BO_ 80 MSG_04: 8 XXX
 SG_ SIGNAL : 24|1@0+ (1,0) [0|1] "" XXX
 SG_ NEW_SIGNAL_1 : 25|1@0+ (1,0) [0|1] "" XXX

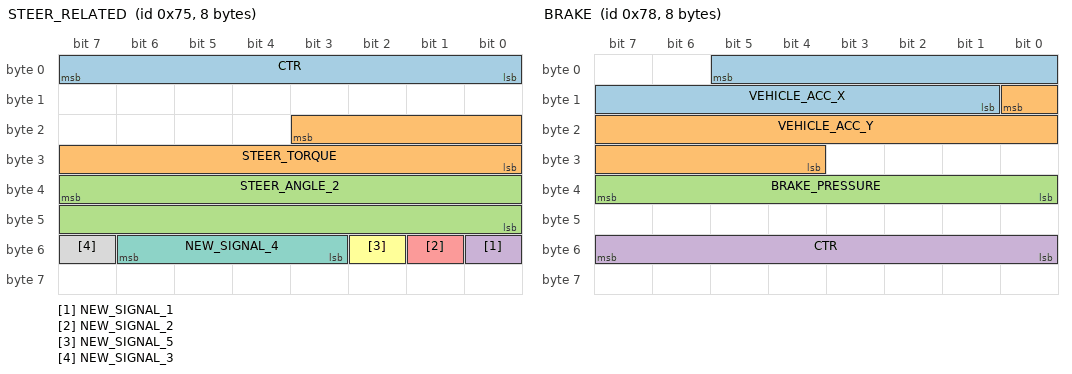
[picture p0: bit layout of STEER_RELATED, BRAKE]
BO_ 117 STEER_RELATED: 8 XXX
 SG_ CTR : 7|8@0+ (1,0) [0|255] "" XXX
 SG_ STEER_TORQUE : 19|12@0+ (1,-2000) [0|255] "" XXX
 SG_ STEER_ANGLE_2 : 39|16@0+ (0.1,-1800) [0|131071] "" XXX
 SG_ NEW_SIGNAL_1 : 48|1@0+ (1,0) [0|1] "" XXX
 SG_ NEW_SIGNAL_2 : 49|1@0+ (1,0) [0|1] "" XXX
 SG_ NEW_SIGNAL_5 : 50|1@0+ (1,0) [0|1] "" XXX
 SG_ NEW_SIGNAL_4 : 54|4@0+ (1,0) [0|31] "" XXX
 SG_ NEW_SIGNAL_3 : 55|1@0+ (1,0) [0|63] "" XXX

BO_ 118 RPM_RELATED: 8 XXX
 SG_ CTR : 7|8@0+ (1,0) [0|127] "" XXX
 SG_ NEW_SIGNAL_2 : 19|12@0+ (1,0) [0|4095] "" XXX

BO_ 120 BRAKE: 8 XXX
 SG_ VEHICLE_ACC_X : 5|13@0+ (0.01,-40) [-40|40] "m/s^2" XXX
 SG_ VEHICLE_ACC_Y : 8|13@0+ (0.001,-4.096) [-4.096|4.096] "m/s^2" XXX
 SG_ BRAKE_PRESSURE : 39|8@0+ (1,0) [0|255] "" XXX
 SG_ CTR : 55|8@0+ (1,0) [0|255] "" XXX

BO_ 121 Lateral_Acceleration: 2 XXX
 SG_ LateralAcceleration : 5|13@0+ (1,0) [0|8191] "" XXX
 SG_ LateralAcceleration_Qf : 6|2@1+ (1,0) [0|3] "" XXX

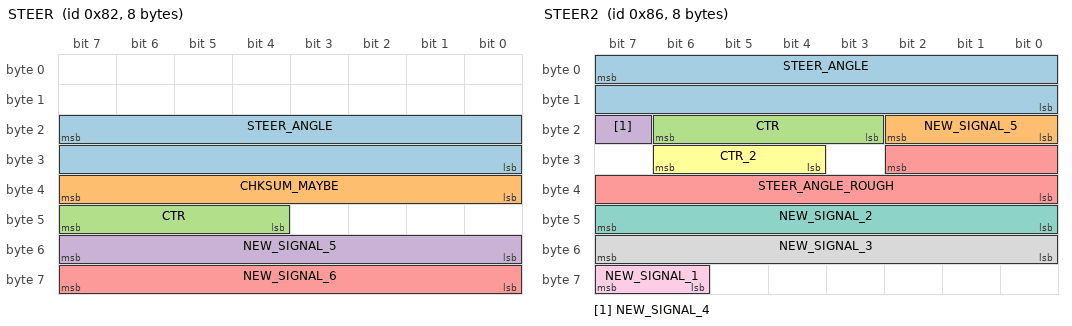
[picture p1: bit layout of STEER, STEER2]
BO_ 130 STEER: 8 XXX
 SG_ STEER_ANGLE : 23|16@0+ (0.05,-1600) [500|-500] "deg" XXX
 SG_ CHKSUM_MAYBE : 39|8@0+ (1,0) [0|255] "" XXX
 SG_ CTR : 47|4@0+ (1,0) [0|255] "" XXX
 SG_ NEW_SIGNAL_5 : 55|8@0+ (1,0) [0|255] "" XXX
 SG_ NEW_SIGNAL_6 : 63|8@0+ (1,0) [0|255] "" XXX

BO_ 134 STEER2: 8 XXX
 SG_ STEER_ANGLE : 7|16@0+ (0.1,-1600) [-500|500] "deg" XXX
 SG_ NEW_SIGNAL_5 : 18|3@0+ (1,0) [0|1] "" XXX
 SG_ CTR : 22|4@0+ (1,0) [0|7] "" XXX
 SG_ NEW_SIGNAL_4 : 23|1@0+ (1,0) [0|1] "" XXX
 SG_ STEER_ANGLE_ROUGH : 26|11@0+ (1,-1000) [0|15] "" XXX
 SG_ CTR_2 : 28|3@1+ (1,0) [0|7] "" XXX
 SG_ NEW_SIGNAL_2 : 47|8@0+ (1,0) [0|7] "" XXX
 SG_ NEW_SIGNAL_3 : 55|8@0+ (1,0) [0|255] "" XXX
 SG_ NEW_SIGNAL_1 : 63|2@0+ (1,0) [0|3] "" XXX

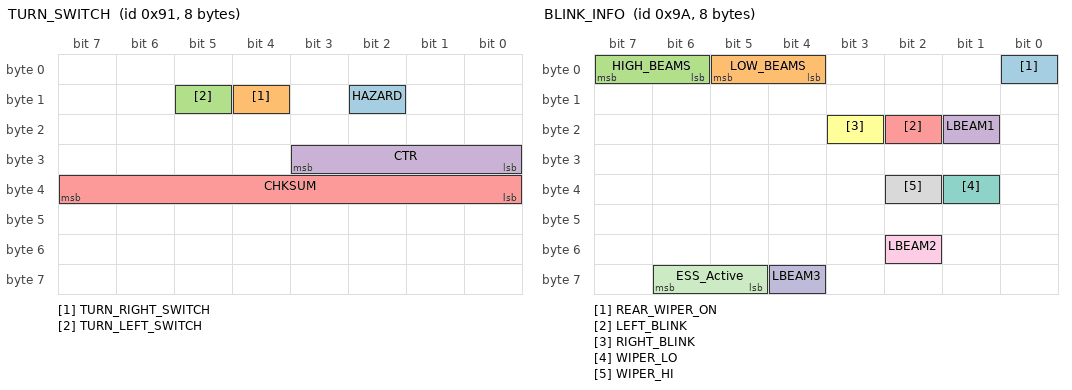
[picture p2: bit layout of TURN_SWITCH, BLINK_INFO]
BO_ 145 TURN_SWITCH: 8 XXX
 SG_ HAZARD : 10|1@0+ (1,0) [0|1] "" XXX
 SG_ TURN_RIGHT_SWITCH : 12|1@0+ (1,0) [0|3] "" XXX
 SG_ TURN_LEFT_SWITCH : 13|1@0+ (1,0) [0|255] "" XXX
 SG_ CTR : 27|4@0+ (1,0) [0|255] "" XXX
 SG_ CHKSUM : 39|8@0+ (1,0) [0|15] "" XXX

BO_ 154 BLINK_INFO: 8 XXX
 SG_ REAR_WIPER_ON : 0|1@0+ (1,0) [0|1] "" XXX
 SG_ LOW_BEAMS : 5|2@0+ (1,0) [0|3] "" XXX
 SG_ HIGH_BEAMS : 7|2@0+ (1,0) [0|3] "" XXX
 SG_ LBEAM1 : 17|1@0+ (1,0) [0|1] "" XXX
 SG_ LEFT_BLINK : 18|1@1+ (1,0) [0|3] "" XXX
 SG_ RIGHT_BLINK : 19|1@0+ (1,0) [0|255] "" XXX
 SG_ WIPER_LO : 33|1@1+ (1,0) [0|31] "" XXX
 SG_ WIPER_HI : 34|1@0+ (1,0) [0|1] "" XXX
 SG_ LBEAM2 : 50|1@0+ (1,0) [0|1] "" XXX
 SG_ LBEAM3 : 60|1@0+ (1,0) [0|1] "" XXX
 SG_ ESS_Active : 61|2@1+ (1,0) [0|3] "" XXX

BO_ 155 MSG_14: 8 XXX

BO_ 157 CRZ_BTNS: 8 XXX
 SG_ CAN_OFF : 0|1@0+ (1,0) [0|1] "" XXX
 SG_ RES : 2|1@0+ (1,0) [0|1] "" XXX
 SG_ SET_P : 4|1@0+ (1,0) [0|1] "" XXX
 SG_ SET_M : 5|1@0+ (1,0) [0|1] "" XXX
 SG_ DISTANCE_MORE : 6|1@0+ (1,0) [0|1] "" XXX
 SG_ DISTANCE_LESS : 7|1@0+ (1,0) [0|1] "" XXX
 SG_ DISTANCE_LESS_INV : 8|1@0+ (1,0) [0|1] "" XXX
 SG_ MODE_Y : 13|1@0+ (1,0) [0|1] "" XXX
 SG_ MODE_X : 14|1@0+ (1,0) [0|1] "" XXX
 SG_ BIT1 : 16|1@0+ (1,0) [0|1] "" XXX
 SG_ CAN_OFF_INV : 17|1@0+ (1,0) [0|1] "" XXX
 SG_ BIT2 : 18|1@0+ (1,0) [0|1] "" XXX
 SG_ RES_INV : 19|1@0+ (1,0) [0|1] "" XXX
 SG_ BIT3 : 20|1@0+ (1,0) [0|1] "" XXX
 SG_ SET_P_INV : 21|1@0+ (1,0) [0|1] "" XXX
 SG_ SET_M_INV : 22|1@0+ (1,0) [0|1] "" XXX
 SG_ DISTANCE_MORE_INV : 23|1@0+ (1,0) [0|1] "" XXX
 SG_ CTR : 29|4@0+ (1,0) [0|15] "" XXX
 SG_ MODE_Y_INV : 30|1@0+ (1,0) [0|1] "" XXX
 SG_ MODE_X_INV : 31|1@0+ (1,0) [0|1] "" XXX

BO_ 158 MSG_05: 8 XXX
 SG_ NEW_SIGNAL_1 : 23|8@0+ (1,0) [0|15] "" XXX
 SG_ NEW_SIGNAL_2 : 47|8@0+ (1,0) [0|255] "" XXX
 SG_ NEW_SIGNAL_3 : 55|8@0+ (1,0) [0|255] "" XXX

BO_ 159 MSG_11: 8 XXX
 SG_ INCREASEING : 39|8@0+ (1,0) [0|255] "" XXX
 SG_ NEW_SIGNAL_1 : 50|4@1+ (1,0) [0|15] "" XXX

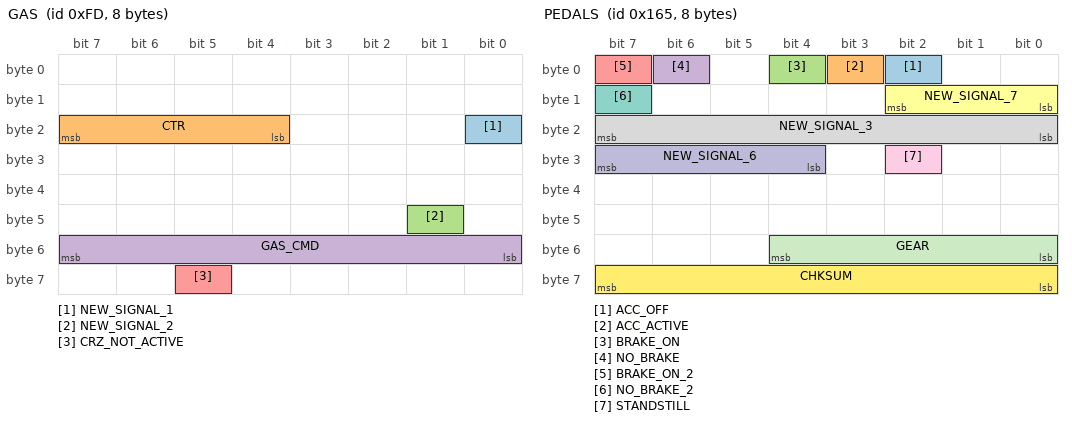
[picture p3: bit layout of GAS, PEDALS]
BO_ 253 GAS: 8 XXX
 SG_ NEW_SIGNAL_1 : 16|1@0+ (1,0) [0|65535] "" XXX
 SG_ CTR : 23|4@0+ (1,0) [0|15] "" XXX
 SG_ NEW_SIGNAL_2 : 41|1@0+ (1,0) [0|255] "" XXX
 SG_ GAS_CMD : 55|8@0+ (1,0) [0|255] "" XXX
 SG_ CRZ_NOT_ACTIVE : 61|1@0+ (1,0) [0|255] "" XXX

BO_ 304 GEAR_RELATED: 8 XXX
 SG_ NEW_SIGNAL_2 : 47|8@0+ (1,0) [0|255] "" XXX
 SG_ NEW_SIGNAL_1 : 55|8@0+ (1,0) [0|255] "" XXX

BO_ 305 NEW_MSG_6: 8 XXX
 SG_ NEW_SIGNAL_1 : 8|1@0+ (1,0) [0|255] "" XXX
 SG_ NEW_SIGNAL_2 : 9|1@0+ (1,0) [0|1] "" XXX
 SG_ NEW_SIGNAL_3 : 10|1@0+ (1,0) [0|1] "" XXX

BO_ 357 PEDALS: 8 XXX
 SG_ ACC_OFF : 2|1@1+ (1,0) [0|15] "" XXX
 SG_ ACC_ACTIVE : 3|1@0+ (1,0) [0|1] "" XXX
 SG_ BRAKE_ON : 4|1@0+ (1,0) [0|1] "" XXX
 SG_ NO_BRAKE : 6|1@0+ (1,0) [0|7] "" XXX
 SG_ BRAKE_ON_2 : 7|1@1+ (1,0) [0|255] "" XXX
 SG_ NEW_SIGNAL_7 : 8|3@1+ (1,0) [0|7] "" XXX
 SG_ NO_BRAKE_2 : 15|1@0+ (1,0) [0|7] "" XXX
 SG_ NEW_SIGNAL_3 : 23|8@0+ (1,0) [0|3] "" XXX
 SG_ STANDSTILL : 26|1@0+ (1,0) [0|16777215] "" XXX
 SG_ NEW_SIGNAL_6 : 31|4@0+ (1,0) [0|1] "" XXX
 SG_ GEAR : 48|5@1+ (1,0) [0|255] "" XXX
 SG_ CHKSUM : 63|8@0+ (1,0) [0|15] "" XXX

BO_ 358 NEW_MSG_28: 8 XXX

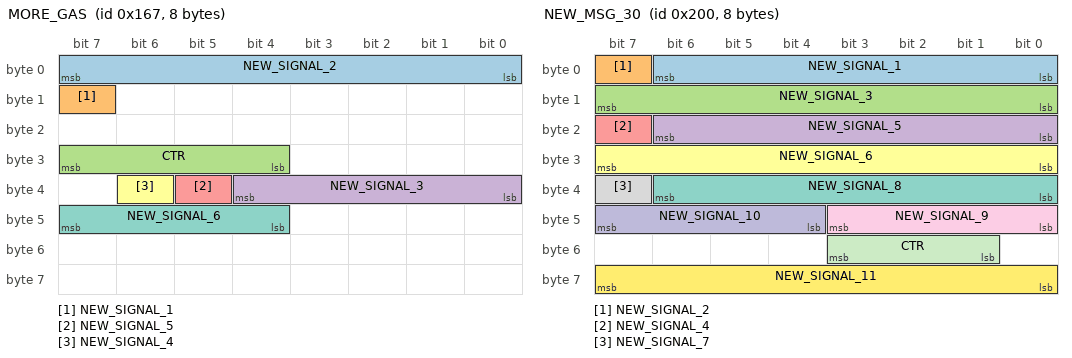
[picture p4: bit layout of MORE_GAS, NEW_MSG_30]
BO_ 359 MORE_GAS: 8 XXX
 SG_ NEW_SIGNAL_2 : 7|8@0+ (1,0) [0|255] "" XXX
 SG_ NEW_SIGNAL_1 : 15|1@0+ (1,0) [0|255] "" XXX
 SG_ CTR : 31|4@0+ (1,0) [0|255] "" XXX
 SG_ NEW_SIGNAL_3 : 36|5@0+ (1,0) [0|255] "" XXX
 SG_ NEW_SIGNAL_5 : 37|1@0+ (1,0) [0|1] "" XXX
 SG_ NEW_SIGNAL_4 : 38|1@1+ (1,0) [0|3] "" XXX
 SG_ NEW_SIGNAL_6 : 47|4@0+ (1,0) [0|255] "" XXX

BO_ 512 NEW_MSG_30: 8 XXX
 SG_ NEW_SIGNAL_1 : 6|7@0+ (1,0) [0|255] "" XXX
 SG_ NEW_SIGNAL_2 : 7|1@0+ (1,0) [0|1] "" XXX
 SG_ NEW_SIGNAL_3 : 15|8@0+ (1,0) [0|255] "" XXX
 SG_ NEW_SIGNAL_5 : 22|7@0+ (1,0) [0|127] "" XXX
 SG_ NEW_SIGNAL_4 : 23|1@0+ (1,0) [0|255] "" XXX
 SG_ NEW_SIGNAL_6 : 31|8@0+ (1,0) [0|255] "" XXX
 SG_ NEW_SIGNAL_8 : 38|7@0+ (1,0) [0|127] "" XXX
 SG_ NEW_SIGNAL_7 : 39|1@0+ (1,0) [0|1] "" XXX
 SG_ NEW_SIGNAL_9 : 40|4@1+ (1,0) [0|15] "" XXX
 SG_ NEW_SIGNAL_10 : 47|4@0+ (1,0) [0|15] "" XXX
 SG_ CTR : 51|3@0+ (1,0) [0|255] "" XXX
 SG_ NEW_SIGNAL_11 : 63|8@0+ (1,0) [0|255] "" XXX

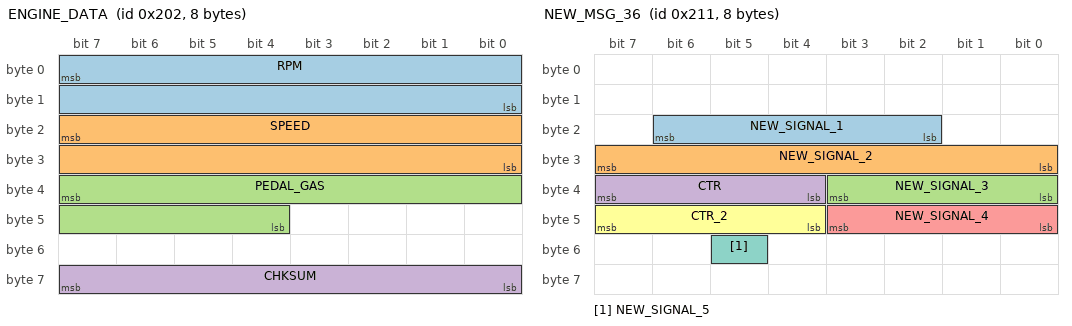
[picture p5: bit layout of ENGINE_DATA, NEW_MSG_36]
BO_ 514 ENGINE_DATA: 8 XXX
 SG_ RPM : 7|16@0+ (0.25,0) [0|8500] "rpm" XXX
 SG_ SPEED : 23|16@0+ (0.01,0) [0|32767] "kph" XXX
 SG_ PEDAL_GAS : 39|12@0+ (1,0) [0|255] "%" XXX
 SG_ CHKSUM : 63|8@0+ (1,0) [0|127] "" XXX

BO_ 529 NEW_MSG_36: 8 XXX
 SG_ NEW_SIGNAL_1 : 22|5@0+ (1,0) [0|65535] "" XXX
 SG_ NEW_SIGNAL_2 : 31|8@0+ (1,0) [0|15] "" XXX
 SG_ NEW_SIGNAL_3 : 32|4@1+ (1,0) [0|3] "" XXX
 SG_ CTR : 39|4@0+ (1,0) [0|255] "" XXX
 SG_ NEW_SIGNAL_4 : 40|4@1+ (1,0) [0|3] "" XXX
 SG_ CTR_2 : 47|4@0+ (1,0) [0|255] "" XXX
 SG_ NEW_SIGNAL_5 : 53|1@0+ (1,0) [0|255] "" XXX

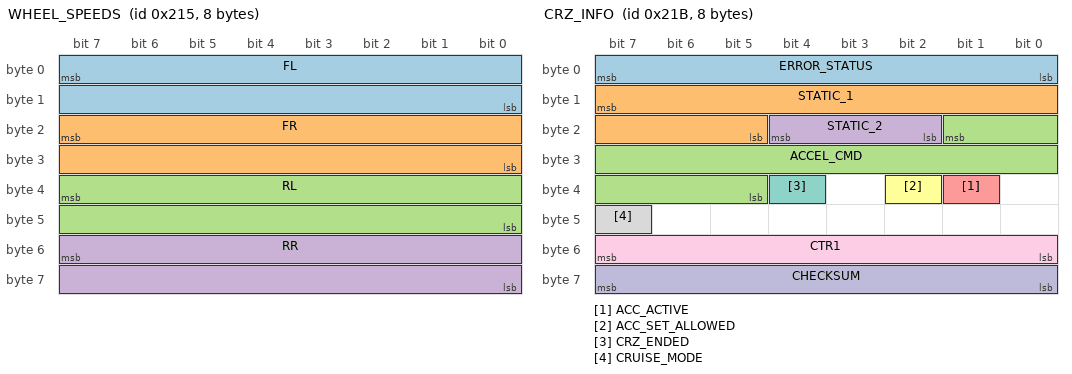
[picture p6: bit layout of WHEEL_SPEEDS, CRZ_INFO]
BO_ 533 WHEEL_SPEEDS: 8 XXX
 SG_ FL : 7|16@0+ (0.01,-100) [0|16383] "kph" XXX
 SG_ FR : 23|16@0+ (0.01,-100) [0|65535] "kph" XXX
 SG_ RL : 39|16@0+ (0.01,-100) [0|15] "kph" XXX
 SG_ RR : 55|16@0+ (0.01,-100) [0|65535] "kph" XXX

BO_ 535 CURVE_CTRS: 8 XXX
 SG_ NEW_SIGNAL_1 : 0|1@0+ (1,0) [0|1] "" XXX
 SG_ NEW_SIGNAL_2 : 1|1@0+ (1,0) [0|1] "" XXX
 SG_ CTR_A_1 : 4|3@0+ (1,0) [0|31] "" XXX
 SG_ CTR_A_2 : 7|3@0+ (1,0) [0|255] "" XXX
 SG_ SEATBELT_MAYBE : 8|1@0+ (1,0) [0|1] "" XXX
 SG_ NEW_SIGNAL_4 : 9|1@0+ (1,0) [0|1] "" XXX
 SG_ CTR_B_1 : 12|3@0+ (1,0) [0|7] "" XXX
 SG_ CTR_B_2 : 15|3@0+ (1,0) [0|7] "" XXX
 SG_ NO_SEATBELT_MAYBE : 16|1@0+ (1,0) [0|1] "" XXX
 SG_ NEW_SIGNAL_6 : 17|1@0+ (1,0) [0|1] "" XXX
 SG_ CTR_C_1 : 20|3@0+ (1,0) [0|7] "" XXX
 SG_ CTR_C_2 : 23|3@0+ (1,0) [0|255] "" XXX
 SG_ NEW_SIGNAL_7 : 24|1@0+ (1,0) [0|1] "" XXX
 SG_ NEW_SIGNAL_8 : 25|1@0+ (1,0) [0|1] "" XXX
 SG_ CTR_D_1 : 28|3@0+ (1,0) [0|7] "" XXX
 SG_ CTR_D_2 : 31|3@0+ (1,0) [0|7] "" XXX
 SG_ SPEED : 39|16@0+ (0.01,0) [0|7] "kph" XXX
 SG_ CTR : 55|8@0+ (1,0) [0|255] "" XXX
 SG_ CHK_MAYBE : 63|8@0+ (1,0) [0|255] "" XXX

BO_ 539 CRZ_INFO: 8 XXX
 SG_ ERROR_STATUS : 7|8@0+ (1,0) [0|255] "" XXX
 SG_ STATIC_1 : 15|11@0+ (1,0) [0|16383] "" XXX
 SG_ ACCEL_CMD : 17|13@0+ (1,-4096) [0|1] "" XXX
 SG_ STATIC_2 : 18|3@1+ (1,0) [0|3] "" XXX
 SG_ ACC_ACTIVE : 33|1@0+ (1,0) [0|1] "" XXX
 SG_ ACC_SET_ALLOWED : 34|1@0+ (1,0) [0|1] "" XXX
 SG_ CRZ_ENDED : 36|1@0+ (1,0) [0|255] "" XXX
 SG_ CRUISE_MODE : 47|1@0+ (1,0) [0|255] "" XXX
 SG_ CTR1 : 55|8@0+ (1,0) [0|255] "" XXX
 SG_ CHECKSUM : 56|8@1+ (1,0) [0|255] "" XXX

BO_ 540 CRZ_CTRL: 8 XXX
 SG_ LANE_LINE_VISIBLE : 0|2@1+ (1,0) [0|7] "" XXX
 SG_ NEW_SIGNAL_2 : 2|1@0+ (1,0) [0|1] "" XXX
 SG_ CRZ_ACTIVE : 3|1@1+ (1,0) [0|1] "" XXX
 SG_ ERROR_STATUS : 6|2@1+ (1,0) [0|3] "" XXX
 SG_ LANE_LINE_TYPE : 8|3@1+ (1,0) [0|7] "" XXX
 SG_ WARN_FLASH_IND : 11|1@1+ (1,0) [0|1] "" XXX
 SG_ WARN_HUD_COLOR : 12|1@1+ (1,0) [0|1] "" XXX
 SG_ STATUS : 13|3@1+ (1,0) [0|7] "" XXX
 SG_ WARN_DRSS_DISTANCE : 16|1@1+ (1,0) [0|3] "" XXX
 SG_ CRZ_AVAILABLE : 17|1@0+ (1,0) [0|1] "" XXX
 SG_ WARN_DISTANCE_SW_STATUS : 18|3@1+ (1,0) [0|7] "" XXX
 SG_ WARN_POPUP_DISPLAY_REQUEST : 22|1@1+ (1,0) [0|1] "" XXX
 SG_ ACC_HAS_LEAD : 23|1@1+ (1,0) [0|1] "" XXX
 SG_ DRSS_DISTANCE : 29|3@1+ (1,0) [0|7] "" XXX
 SG_ WARN_PCS_FAILED : 32|1@1+ (1,0) [0|1] "" XXX
 SG_ WARN_ACC_DEACTIVATED : 33|1@1+ (1,0) [0|1] "" XXX
 SG_ WARN_ACC_FAILED : 34|2@1+ (1,0) [0|3] "" XXX
 SG_ WARN_FSC_STATUS : 40|3@1+ (1,0) [0|7] "" XXX
 SG_ a_3 : 43|4@1+ (1,0) [0|15] "" XXX
 SG_ WARN_DRSS_FAILED : 47|1@1+ (1,0) [0|1] "" XXX
 SG_ BRAKE_WARN : 48|4@1+ (1,0) [0|15] "" XXX
 SG_ CRZ_ACTIVE_2 : 52|1@1+ (1,0) [0|1] "" XXX
 SG_ WARN_RADAR_BLOCKED : 53|3@1+ (1,0) [0|7] "" XXX
 SG_ NEW_SIGNAL_1 : 63|8@0+ (1,0) [0|255] "" XXX

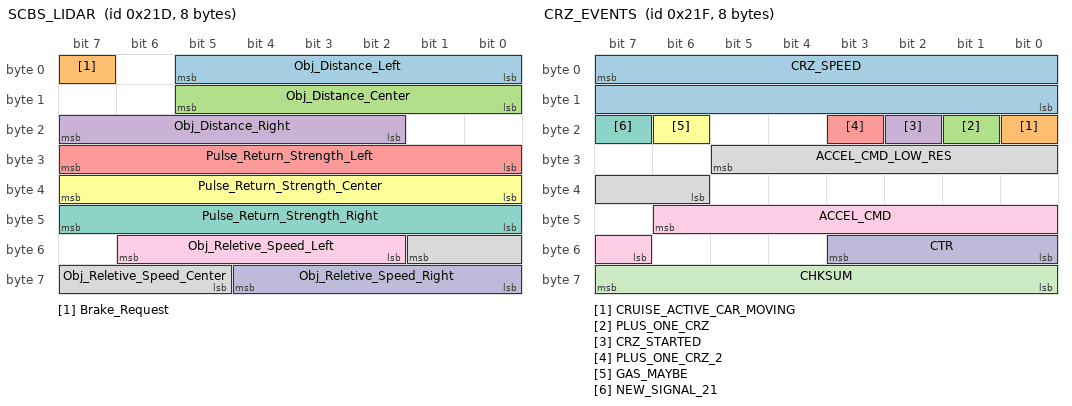
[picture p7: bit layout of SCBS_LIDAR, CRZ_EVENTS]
BO_ 541 SCBS_LIDAR: 8 XXX
 SG_ Obj_Distance_Left : 0|6@1+ (1,0) [0|63] "" XXX
 SG_ Brake_Request : 7|1@1+ (1,0) [0|1] "" XXX
 SG_ Obj_Distance_Center : 8|6@1+ (1,0) [0|63] "" XXX
 SG_ Obj_Distance_Right : 18|6@1+ (1,0) [0|63] "" XXX
 SG_ Pulse_Return_Strength_Left : 24|8@1+ (1,0) [0|255] "" XXX
 SG_ Pulse_Return_Strength_Center : 32|8@1+ (1,0) [0|255] "" XXX
 SG_ Pulse_Return_Strength_Right : 40|8@1+ (1,0) [0|255] "" XXX
 SG_ Obj_Reletive_Speed_Center : 49|5@0+ (1,0) [0|31] "" XXX
 SG_ Obj_Reletive_Speed_Left : 50|5@1+ (1,0) [0|31] "" XXX
 SG_ Obj_Reletive_Speed_Right : 56|5@1+ (1,0) [0|31] "" XXX

BO_ 542 NEW_MSG_33: 8 XXX
 SG_ CTR : 48|4@1+ (1,0) [0|15] "" XXX
 SG_ CTR2 : 56|4@1+ (1,0) [0|15] "" XXX

BO_ 543 CRZ_EVENTS: 8 XXX
 SG_ CRZ_SPEED : 7|16@0+ (0.005,-0.5) [0|328] "kph" XXX
 SG_ CRUISE_ACTIVE_CAR_MOVING : 16|1@0+ (1,0) [0|1] "" XXX
 SG_ PLUS_ONE_CRZ : 17|1@0+ (1,0) [0|255] "" XXX
 SG_ CRZ_STARTED : 18|1@0+ (1,0) [0|1] "" XXX
 SG_ PLUS_ONE_CRZ_2 : 19|1@0+ (1,0) [0|1] "" XXX
 SG_ GAS_MAYBE : 22|1@0+ (1,0) [0|1] "" XXX
 SG_ NEW_SIGNAL_21 : 23|1@0+ (1,0) [0|15] "" XXX
 SG_ ACCEL_CMD_LOW_RES : 29|8@0- (1,0) [0|255] "" XXX
 SG_ ACCEL_CMD : 46|8@0- (1,0) [0|15] "" XXX
 SG_ CTR : 51|4@0+ (1,0) [0|15] "" XXX
 SG_ CHKSUM : 63|8@0+ (1,0) [0|15] "" XXX

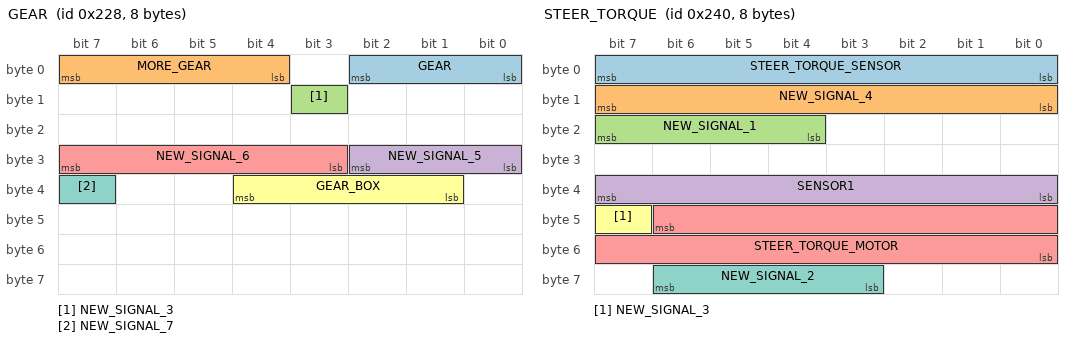
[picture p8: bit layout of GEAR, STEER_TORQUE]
BO_ 552 GEAR: 8 XXX
 SG_ GEAR : 2|3@0+ (1,0) [0|7] "" XXX
 SG_ MORE_GEAR : 7|4@0+ (1,0) [0|15] "" XXX
 SG_ NEW_SIGNAL_3 : 11|1@0+ (1,0) [0|1] "" XXX
 SG_ NEW_SIGNAL_5 : 26|3@0+ (1,0) [0|255] "" XXX
 SG_ NEW_SIGNAL_6 : 31|5@0+ (1,0) [0|31] "" XXX
 SG_ GEAR_BOX : 36|4@0+ (1,0) [0|15] "" XXX
 SG_ NEW_SIGNAL_7 : 39|1@0+ (1,0) [0|255] "" XXX

BO_ 576 STEER_TORQUE: 8 XXX
 SG_ STEER_TORQUE_SENSOR : 7|8@0+ (1,-127) [-85|85] "" XXX
 SG_ NEW_SIGNAL_4 : 15|8@0+ (1,0) [0|127] "" XXX
 SG_ NEW_SIGNAL_1 : 23|4@0+ (1,0) [0|255] "" XXX
 SG_ SENSOR1 : 39|8@0+ (1,-128) [0|127] "" XXX
 SG_ STEER_TORQUE_MOTOR : 46|15@0- (0.1,0) [-3000|3000] "tbd" XXX
 SG_ NEW_SIGNAL_3 : 47|1@0+ (1,0) [0|1] "" XXX
 SG_ NEW_SIGNAL_2 : 62|4@0+ (1,0) [0|31] "" XXX

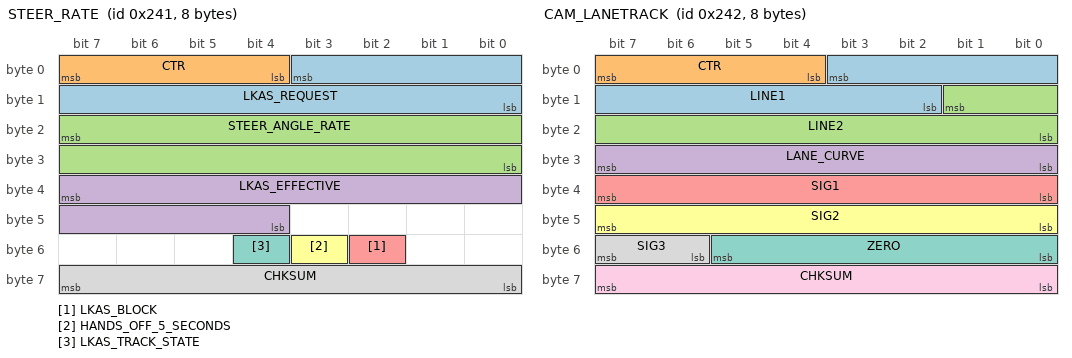
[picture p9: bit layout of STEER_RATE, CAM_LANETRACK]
BO_ 577 STEER_RATE: 8 XXX
 SG_ LKAS_REQUEST : 3|12@0+ (1,-2048) [0|15] "" XXX
 SG_ CTR : 7|4@0+ (1,0) [0|15] "" XXX
 SG_ STEER_ANGLE_RATE : 23|16@0+ (0.25,-8192) [0|1] "deg/s" XXX
 SG_ LKAS_EFFECTIVE : 39|12@0+ (1,-2048) [0|255] "" XXX
 SG_ LKAS_BLOCK : 50|1@1+ (1,0) [0|3] "" XXX
 SG_ HANDS_OFF_5_SECONDS : 51|1@0+ (1,0) [0|1] "" XXX
 SG_ LKAS_TRACK_STATE : 52|1@0+ (1,0) [0|3] "" XXX
 SG_ CHKSUM : 63|8@0+ (1,0) [0|255] "" XXX

BO_ 578 CAM_LANETRACK: 8 XXX
 SG_ LINE1 : 3|10@0+ (1,-686) [0|1] "" XXX
 SG_ CTR : 7|4@0+ (1,0) [0|15] "" XXX
 SG_ LINE2 : 9|10@0+ (1,-686) [0|255] "" XXX
 SG_ LANE_CURVE : 31|8@0+ (1,-127) [0|255] "" XXX
 SG_ SIG1 : 39|8@0+ (1,-128) [0|255] "" XXX
 SG_ SIG2 : 47|8@0+ (1,0) [0|255] "" XXX
 SG_ ZERO : 53|6@0+ (1,0) [0|63] "" XXX
 SG_ SIG3 : 55|2@0+ (1,0) [0|3] "" XXX
 SG_ CHKSUM : 63|8@0+ (1,0) [0|255] "" XXX

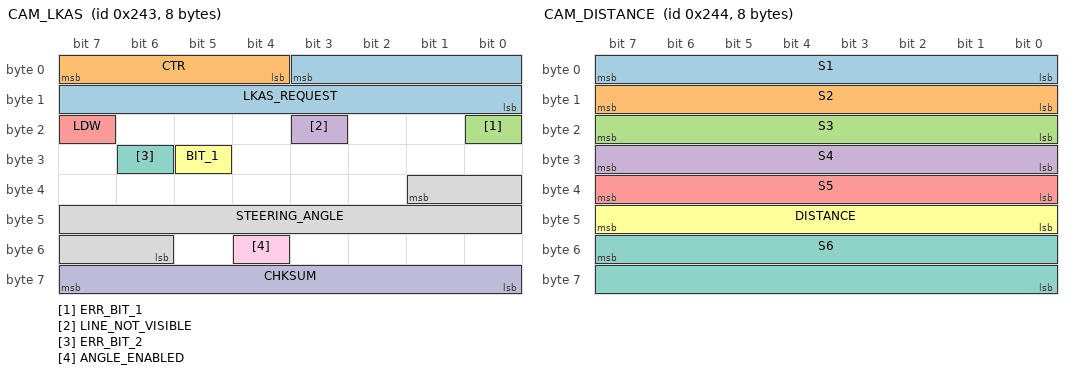
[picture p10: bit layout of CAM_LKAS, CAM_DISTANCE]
BO_ 579 CAM_LKAS: 8 XXX
 SG_ LKAS_REQUEST : 3|12@0+ (1,-2048) [0|2048] "" XXX
 SG_ CTR : 7|4@0+ (1,0) [0|15] "" XXX
 SG_ ERR_BIT_1 : 16|1@0+ (1,0) [0|1] "" XXX
 SG_ LINE_NOT_VISIBLE : 19|1@0+ (1,0) [0|1] "" XXX
 SG_ LDW : 23|1@0+ (1,0) [0|1] "" XXX
 SG_ BIT_1 : 29|1@0+ (1,0) [0|1] "" XXX
 SG_ ERR_BIT_2 : 30|1@0+ (1,0) [0|1] "" XXX
 SG_ STEERING_ANGLE : 33|12@0+ (1,-2048) [-2048|2047] "" XXX
 SG_ ANGLE_ENABLED : 52|1@0+ (1,0) [0|1] "" XXX
 SG_ CHKSUM : 63|8@0+ (1,0) [0|15] "" XXX

BO_ 580 CAM_DISTANCE: 8 XXX
 SG_ S1 : 0|8@1+ (1,0) [0|127] "" XXX
 SG_ S2 : 15|8@0+ (1,0) [0|1] "" XXX
 SG_ S3 : 16|8@1+ (1,0) [0|3] "" XXX
 SG_ S4 : 24|8@1+ (1,0) [0|31] "" XXX
 SG_ S5 : 32|8@1+ (1,0) [0|255] "" XXX
 SG_ DISTANCE : 47|8@0+ (1,0) [0|65535] "" XXX
 SG_ S6 : 55|16@0+ (1,0) [0|255] "" XXX

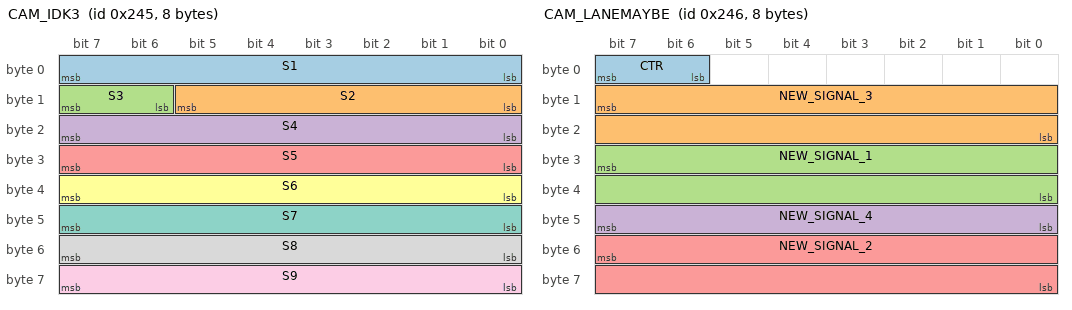
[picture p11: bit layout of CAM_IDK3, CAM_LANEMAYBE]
BO_ 581 CAM_IDK3: 8 XXX
 SG_ S1 : 0|8@1+ (1,0) [0|15] "" XXX
 SG_ S2 : 8|6@1+ (1,0) [0|255] "" XXX
 SG_ S3 : 15|2@0+ (1,0) [0|3] "" XXX
 SG_ S4 : 16|8@1+ (1,0) [0|15] "" XXX
 SG_ S5 : 24|8@1+ (1,0) [0|255] "" XXX
 SG_ S6 : 32|8@1+ (1,0) [0|255] "" XXX
 SG_ S7 : 40|8@1+ (1,0) [0|3] "" XXX
 SG_ S8 : 48|8@1+ (1,0) [0|255] "" XXX
 SG_ S9 : 56|8@1+ (1,0) [0|255] "" XXX

BO_ 582 CAM_LANEMAYBE: 8 XXX
 SG_ CTR : 7|2@0+ (1,0) [0|3] "" XXX
 SG_ NEW_SIGNAL_3 : 15|16@0+ (1,0) [0|65535] "" XXX
 SG_ NEW_SIGNAL_1 : 31|16@0- (1,0) [0|65535] "" XXX
 SG_ NEW_SIGNAL_4 : 40|8@1+ (1,0) [0|127] "" XXX
 SG_ NEW_SIGNAL_2 : 55|16@0+ (1,0) [0|65535] "" XXX

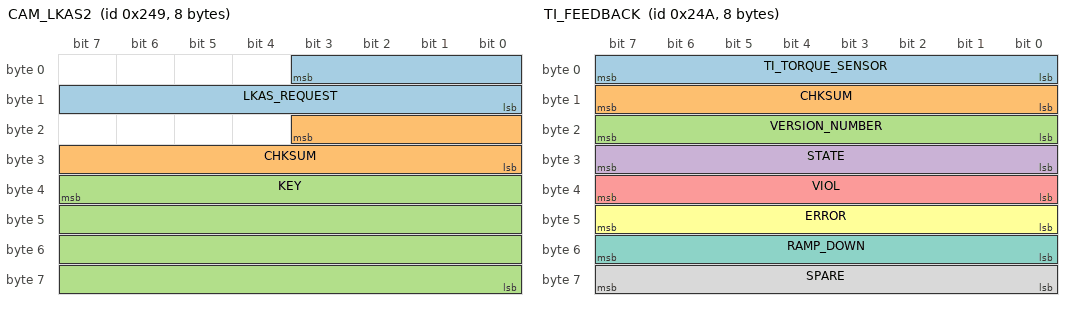
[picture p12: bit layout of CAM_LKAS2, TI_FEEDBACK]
BO_ 585 CAM_LKAS2: 8 XXX
 SG_ LKAS_REQUEST : 3|12@0+ (1,-2048) [0|2048] "" XXX
 SG_ CHKSUM : 19|12@0+ (1,-2048) [0|2048] "" XXX
 SG_ KEY : 39|32@0+ (1,0) [3294744159|3294744161] "" XXX

BO_ 586 TI_FEEDBACK: 8 XXX
 SG_ TI_TORQUE_SENSOR : 7|8@0+ (1,-127) [-85|85] "" XXX
 SG_ CHKSUM : 15|8@0+ (1,-127) [-127|128] "" XXX
 SG_ VERSION_NUMBER : 23|8@0+ (1,0) [0|255] "" XXX
 SG_ STATE : 31|8@0+ (1,0) [0|3] "" XXX
 SG_ VIOL : 39|8@0+ (1,0) [0|255] "" XXX
 SG_ ERROR : 47|8@0+ (1,0) [0|255] "" XXX
 SG_ RAMP_DOWN : 55|8@0+ (1,0) [0|1] "" XXX
 SG_ SPARE : 63|8@0+ (1,0) [0|255] "" XXX

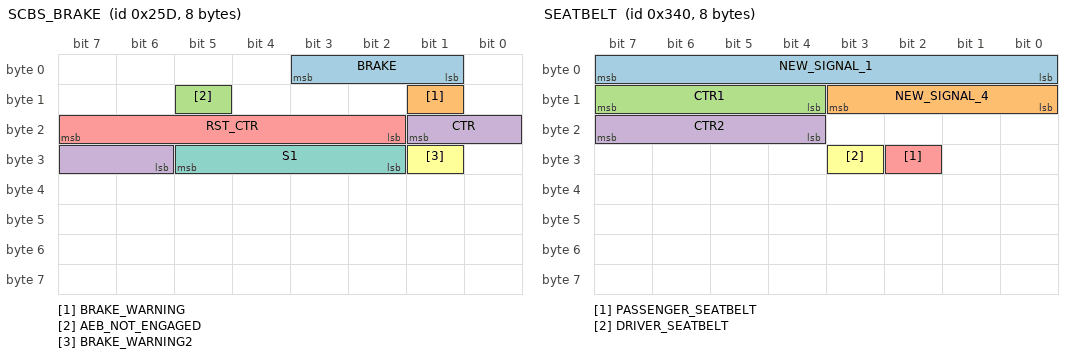
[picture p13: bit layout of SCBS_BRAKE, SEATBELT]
BO_ 605 SCBS_BRAKE: 8 XXX
 SG_ BRAKE : 3|3@0+ (1,0) [0|7] "" XXX
 SG_ BRAKE_WARNING : 9|1@0+ (1,0) [0|255] "" XXX
 SG_ AEB_NOT_ENGAGED : 13|1@0+ (1,0) [0|1] "" XXX
 SG_ CTR : 17|4@0+ (1,0) [0|255] "" XXX
 SG_ RST_CTR : 23|6@0+ (1,0) [0|63] "" XXX
 SG_ BRAKE_WARNING2 : 25|1@0+ (1,0) [0|1] "" XXX
 SG_ S1 : 29|4@0+ (1,0) [0|31] "" XXX

BO_ 628 MSG_06: 8 XXX

BO_ 832 SEATBELT: 8 XXX
 SG_ NEW_SIGNAL_1 : 7|8@0+ (1,0) [0|255] "" XXX
 SG_ NEW_SIGNAL_4 : 8|4@1+ (1,0) [0|3] "" XXX
 SG_ CTR1 : 15|4@0+ (1,0) [0|15] "" XXX
 SG_ CTR2 : 23|4@0+ (1,0) [0|255] "" XXX
 SG_ PASSENGER_SEATBELT : 26|1@1+ (1,0) [0|7] "" XXX
 SG_ DRIVER_SEATBELT : 27|1@0+ (1,0) [0|1] "" XXX

BO_ 976 MSG_15: 8 XXX
 SG_ NEW_SIGNAL_1 : 55|1@0+ (1,0) [0|255] "" XXX
 SG_ NEW_SIGNAL_2 : 61|6@0+ (1,0) [0|1] "" XXX

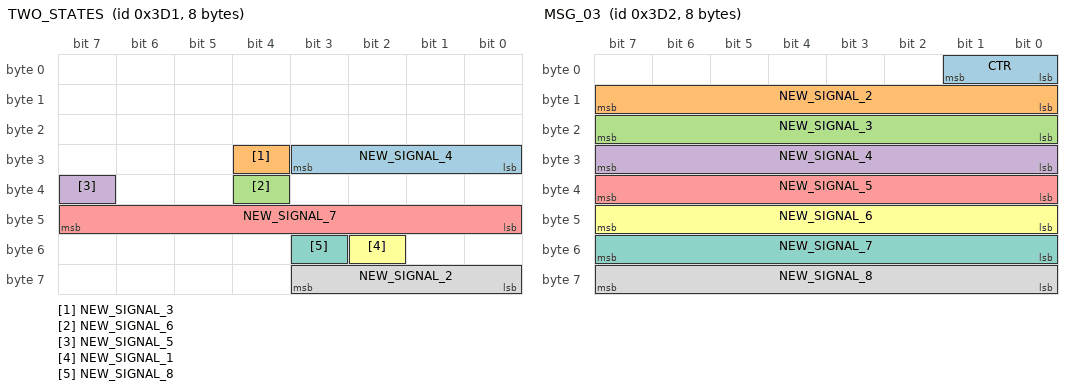
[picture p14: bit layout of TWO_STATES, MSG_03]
BO_ 977 TWO_STATES: 8 XXX
 SG_ NEW_SIGNAL_4 : 24|4@1+ (1,0) [0|3] "" XXX
 SG_ NEW_SIGNAL_3 : 28|1@0+ (1,0) [0|255] "" XXX
 SG_ NEW_SIGNAL_6 : 36|1@0+ (1,0) [0|1] "" XXX
 SG_ NEW_SIGNAL_5 : 39|1@0+ (1,0) [0|1] "" XXX
 SG_ NEW_SIGNAL_7 : 47|8@0+ (1,0) [0|1] "" XXX
 SG_ NEW_SIGNAL_1 : 50|1@1+ (1,0) [0|7] "" XXX
 SG_ NEW_SIGNAL_8 : 51|1@0+ (1,0) [0|1] "" XXX
 SG_ NEW_SIGNAL_2 : 56|4@1+ (1,0) [0|7] "" XXX

BO_ 978 MSG_03: 8 XXX
 SG_ CTR : 1|2@0+ (1,0) [0|255] "" XXX
 SG_ NEW_SIGNAL_2 : 15|8@0+ (1,0) [0|255] "" XXX
 SG_ NEW_SIGNAL_3 : 23|8@0+ (1,0) [0|1] "" XXX
 SG_ NEW_SIGNAL_4 : 31|8@0+ (1,0) [0|255] "" XXX
 SG_ NEW_SIGNAL_5 : 39|8@0+ (1,0) [0|255] "" XXX
 SG_ NEW_SIGNAL_6 : 47|8@0+ (1,0) [0|255] "" XXX
 SG_ NEW_SIGNAL_7 : 55|8@0+ (1,0) [0|255] "" XXX
 SG_ NEW_SIGNAL_8 : 63|8@0+ (1,0) [0|255] "" XXX

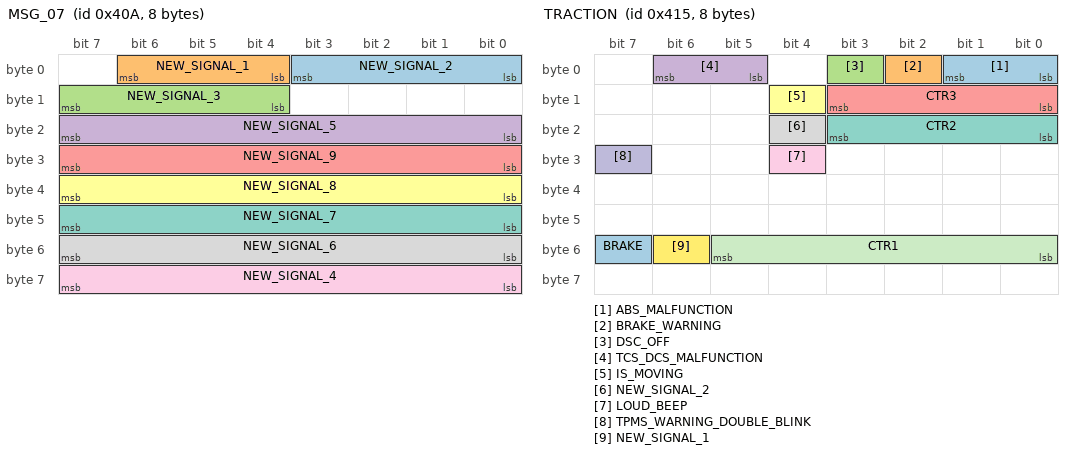
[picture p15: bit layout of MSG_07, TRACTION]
BO_ 1034 MSG_07: 8 XXX
 SG_ NEW_SIGNAL_2 : 0|4@1+ (1,0) [0|3] "" XXX
 SG_ NEW_SIGNAL_1 : 6|3@0+ (1,0) [0|3] "" XXX
 SG_ NEW_SIGNAL_3 : 15|4@0+ (1,0) [0|15] "" XXX
 SG_ NEW_SIGNAL_5 : 23|8@0+ (1,0) [0|255] "" XXX
 SG_ NEW_SIGNAL_9 : 31|8@0+ (1,0) [0|255] "" XXX
 SG_ NEW_SIGNAL_8 : 39|8@0+ (1,0) [0|255] "" XXX
 SG_ NEW_SIGNAL_7 : 47|8@0+ (1,0) [0|255] "" XXX
 SG_ NEW_SIGNAL_6 : 55|8@0+ (1,0) [0|255] "" XXX
 SG_ NEW_SIGNAL_4 : 63|8@0+ (1,0) [0|255] "" XXX

BO_ 1045 TRACTION: 8 XXX
 SG_ ABS_MALFUNCTION : 1|2@0+ (1,0) [0|3] "" XXX
 SG_ BRAKE_WARNING : 2|1@0+ (1,0) [0|1] "" XXX
 SG_ DSC_OFF : 3|1@0+ (1,0) [0|1] "" XXX
 SG_ TCS_DCS_MALFUNCTION : 6|2@0+ (1,0) [0|3] "" XXX
 SG_ CTR3 : 8|4@1+ (1,0) [0|15] "" XXX
 SG_ IS_MOVING : 12|1@0+ (1,0) [0|3] "" XXX
 SG_ CTR2 : 19|4@0+ (1,0) [0|31] "" XXX
 SG_ NEW_SIGNAL_2 : 20|1@0+ (1,0) [0|3] "" XXX
 SG_ LOUD_BEEP : 28|1@0+ (1,0) [0|1] "" XXX
 SG_ TPMS_WARNING_DOUBLE_BLINK : 31|1@0+ (1,0) [0|1] "" XXX
 SG_ CTR1 : 53|6@0+ (1,0) [0|255] "" XXX
 SG_ NEW_SIGNAL_1 : 54|1@0+ (1,0) [0|1] "" XXX
 SG_ BRAKE : 55|1@0+ (1,0) [0|1] "" XXX

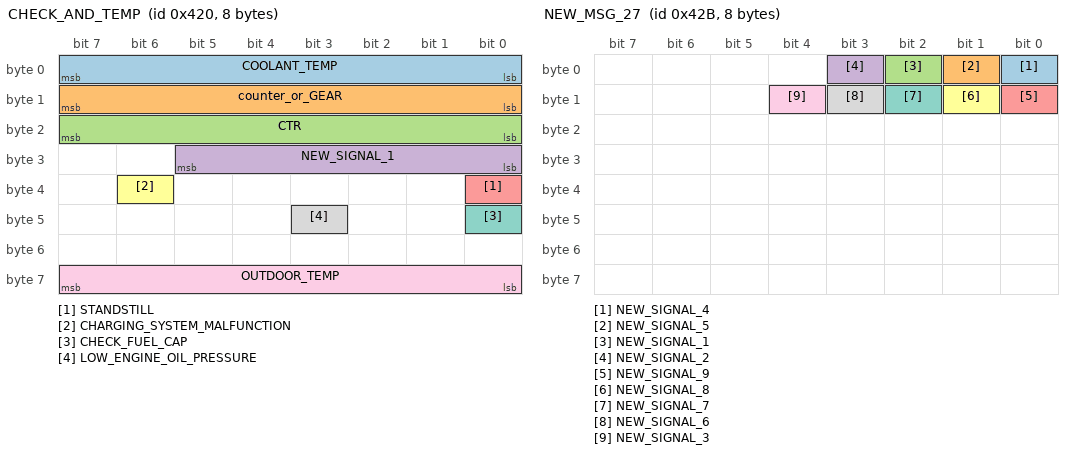
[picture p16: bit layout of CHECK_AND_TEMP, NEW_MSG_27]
BO_ 1056 CHECK_AND_TEMP: 8 XXX
 SG_ COOLANT_TEMP : 7|8@0+ (1,0) [0|255] "" XXX
 SG_ counter_or_GEAR : 15|8@0+ (1,0) [0|255] "" XXX
 SG_ CTR : 23|8@0+ (1,0) [0|255] "" XXX
 SG_ NEW_SIGNAL_1 : 29|6@0+ (1,0) [0|255] "" XXX
 SG_ STANDSTILL : 32|1@0+ (1,0) [0|255] "" XXX
 SG_ CHARGING_SYSTEM_MALFUNCTION : 38|1@0+ (1,0) [0|1] "" XXX
 SG_ CHECK_FUEL_CAP : 40|1@0+ (1,0) [0|1] "" XXX
 SG_ LOW_ENGINE_OIL_PRESSURE : 43|1@0+ (1,0) [0|1] "" XXX
 SG_ OUTDOOR_TEMP : 63|8@0+ (0.25,-63) [0|255] "cel" XXX

BO_ 1067 NEW_MSG_27: 8 XXX
 SG_ NEW_SIGNAL_4 : 0|1@0+ (1,0) [0|1] "" XXX
 SG_ NEW_SIGNAL_5 : 1|1@0+ (1,0) [0|1] "" XXX
 SG_ NEW_SIGNAL_1 : 2|1@0+ (1,0) [0|1] "" XXX
 SG_ NEW_SIGNAL_2 : 3|1@0+ (1,0) [0|1] "" XXX
 SG_ NEW_SIGNAL_9 : 8|1@0+ (1,0) [0|1] "" XXX
 SG_ NEW_SIGNAL_8 : 9|1@0+ (1,0) [0|1] "" XXX
 SG_ NEW_SIGNAL_7 : 10|1@0+ (1,0) [0|1] "" XXX
 SG_ NEW_SIGNAL_6 : 11|1@1+ (1,0) [0|3] "" XXX
 SG_ NEW_SIGNAL_3 : 12|1@0+ (1,0) [0|1] "" XXX

BO_ 1070 2017_1: 8 XXX

BO_ 1078 HVAC: 8 XXX
 SG_ NEW_SIGNAL_1 : 2|1@0+ (1,0) [0|1] "" XXX
 SG_ NEW_SIGNAL_2 : 8|1@0+ (1,0) [0|255] "" XXX
 SG_ NEW_SIGNAL_3 : 23|1@0+ (1,0) [0|65535] "" XXX
 SG_ NEW_SIGNAL_4 : 56|5@0+ (1,0) [0|255] "" XXX

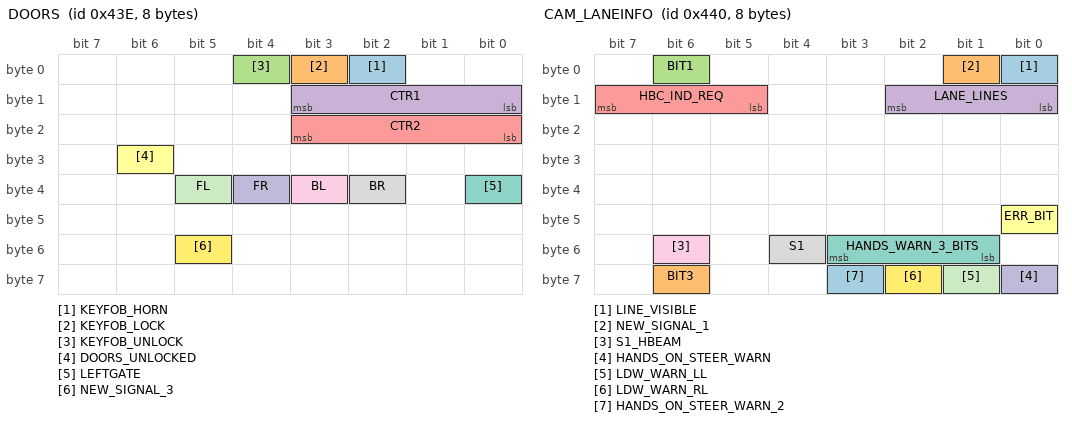
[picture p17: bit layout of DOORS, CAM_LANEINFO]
BO_ 1086 DOORS: 8 XXX
 SG_ KEYFOB_HORN : 2|1@0+ (1,0) [0|1] "" XXX
 SG_ KEYFOB_LOCK : 3|1@0+ (1,0) [0|1] "" XXX
 SG_ KEYFOB_UNLOCK : 4|1@0+ (1,0) [0|1] "" XXX
 SG_ CTR1 : 8|4@1+ (1,0) [0|3] "" XXX
 SG_ CTR2 : 16|4@1+ (1,0) [0|15] "" XXX
 SG_ DOORS_UNLOCKED : 30|1@0+ (1,0) [0|255] "" XXX
 SG_ LEFTGATE : 32|1@0+ (1,0) [0|1] "" XXX
 SG_ BR : 34|1@0+ (1,0) [0|1] "" XXX
 SG_ BL : 35|1@0+ (1,0) [0|1] "" XXX
 SG_ FR : 36|1@0+ (1,0) [0|1] "" XXX
 SG_ FL : 37|1@0+ (1,0) [0|255] "" XXX
 SG_ NEW_SIGNAL_3 : 53|1@0+ (1,0) [0|255] "" XXX

BO_ 1088 CAM_LANEINFO: 8 XXX
 SG_ LINE_VISIBLE : 0|1@0+ (1,0) [0|3] "" XXX
 SG_ NEW_SIGNAL_1 : 1|1@0+ (1,0) [0|1] "" XXX
 SG_ BIT1 : 6|1@0+ (1,0) [0|65535] "" XXX
 SG_ LANE_LINES : 10|3@0+ (1,0) [0|3] "" XXX
 SG_ HBC_IND_REQ : 15|3@0+ (1,0) [0|15] "" XXX
 SG_ ERR_BIT : 40|1@0+ (1,0) [0|1] "" XXX
 SG_ HANDS_WARN_3_BITS : 51|3@0+ (1,0) [0|7] "" XXX
 SG_ S1 : 52|1@0+ (1,0) [0|1] "" XXX
 SG_ S1_HBEAM : 54|1@0+ (1,0) [0|31] "" XXX
 SG_ HANDS_ON_STEER_WARN : 56|1@0+ (1,0) [0|3] "" XXX
 SG_ LDW_WARN_LL : 57|1@0+ (1,0) [0|1] "" XXX
 SG_ LDW_WARN_RL : 58|1@0+ (1,0) [0|1] "" XXX
 SG_ HANDS_ON_STEER_WARN_2 : 59|1@0+ (1,0) [0|1] "" XXX
 SG_ BIT3 : 62|1@0+ (1,0) [0|3] "" XXX

BO_ 1114 NEW_MSG_4: 8 XXX

BO_ 1115 MSG_02: 8 XXX
 SG_ CTR : 2|3@0+ (1,0) [0|255] "" XXX
 SG_ NEW_SIGNAL_2 : 15|8@0+ (1,0) [0|255] "" XXX
 SG_ NEW_SIGNAL_4 : 23|8@0+ (1,0) [0|255] "" XXX
 SG_ NEW_SIGNAL_5 : 31|8@0+ (1,0) [0|255] "" XXX
 SG_ NEW_SIGNAL_6 : 39|8@0+ (1,0) [0|255] "" XXX
 SG_ NEW_SIGNAL_1 : 47|16@0+ (1,0) [0|65535] "" XXX
 SG_ NEW_SIGNAL_3 : 63|1@0+ (1,0) [0|1] "" XXX

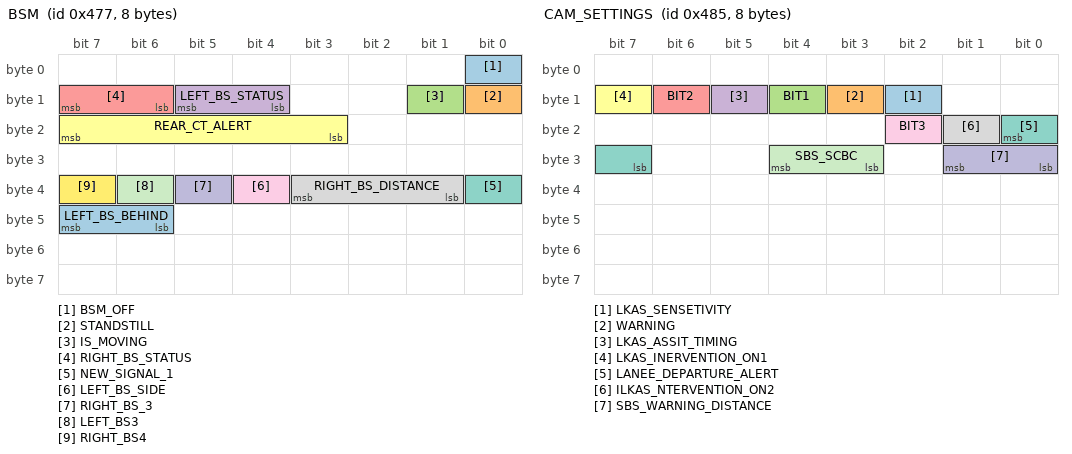
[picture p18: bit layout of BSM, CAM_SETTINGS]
BO_ 1143 BSM: 8 XXX
 SG_ BSM_OFF : 0|1@0+ (1,0) [0|1] "" XXX
 SG_ STANDSTILL : 8|1@0+ (1,0) [0|1] "" XXX
 SG_ IS_MOVING : 9|1@0+ (1,0) [0|1] "" XXX
 SG_ LEFT_BS_STATUS : 13|2@0+ (1,0) [0|3] "" XXX
 SG_ RIGHT_BS_STATUS : 15|2@0+ (1,0) [0|3] "" XXX
 SG_ REAR_CT_ALERT : 23|5@0+ (1,0) [0|63] "" XXX
 SG_ NEW_SIGNAL_1 : 32|1@0+ (1,0) [0|1] "" XXX
 SG_ RIGHT_BS_DISTANCE : 35|3@0+ (1,0) [0|1] "" XXX
 SG_ LEFT_BS_SIDE : 36|1@0+ (1,0) [0|1] "" XXX
 SG_ RIGHT_BS_3 : 37|1@0+ (1,0) [0|1] "" XXX
 SG_ LEFT_BS3 : 38|1@0+ (1,0) [0|1] "" XXX
 SG_ RIGHT_BS4 : 39|1@0+ (1,0) [0|1] "" XXX
 SG_ LEFT_BS_BEHIND : 46|2@1+ (1,0) [0|16777215] "" XXX

BO_ 1154 MSG_08: 8 XXX

BO_ 1157 CAM_SETTINGS: 8 XXX
 SG_ LKAS_SENSETIVITY : 10|1@0+ (1,0) [0|1] "" XXX
 SG_ WARNING : 11|1@0+ (1,0) [0|1] "" XXX
 SG_ BIT1 : 12|1@0+ (1,0) [0|7] "" XXX
 SG_ LKAS_ASSIT_TIMING : 13|1@0+ (1,0) [0|1] "" XXX
 SG_ BIT2 : 14|1@0+ (1,0) [0|1] "" XXX
 SG_ LKAS_INERVENTION_ON1 : 15|1@0+ (1,0) [0|1] "" XXX
 SG_ LANEE_DEPARTURE_ALERT : 16|2@0+ (1,0) [0|1] "" XXX
 SG_ ILKAS_NTERVENTION_ON2 : 17|1@0+ (1,0) [0|255] "" XXX
 SG_ BIT3 : 18|1@0+ (1,0) [0|1] "" XXX
 SG_ SBS_WARNING_DISTANCE : 25|2@0+ (1,0) [0|127] "" XXX
 SG_ SBS_SCBC : 28|2@0+ (1,0) [0|7] "" XXX

BO_ 1160 CAM_Empty3: 8 XXX
 SG_ NEW_SIGNAL_1 : 47|24@0+ (1,0) [0|16777215] "" XXX

BO_ 1177 RADAR_499_STATIC: 8 XXX

BO_ 1180 last_byte_roughRPM: 8 XXX
 SG_ NEW_SIGNAL_1 : 63|8@0+ (1,0) [0|255] "" XXX

BO_ 1238 TEMPERATURE: 8 XXX
 SG_ TEMPERATURE_MAYBE : 47|8@0+ (1,0) [0|4294967295] "" XXX

BO_ 1242 NEW_MSG_37: 8 XXX

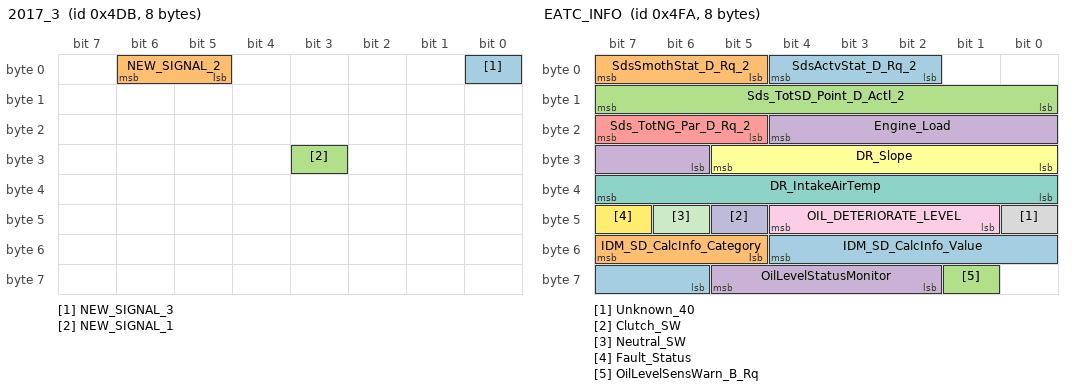
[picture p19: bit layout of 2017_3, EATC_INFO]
BO_ 1243 2017_3: 8 XXX
 SG_ NEW_SIGNAL_3 : 0|1@0+ (1,0) [0|1] "" XXX
 SG_ NEW_SIGNAL_2 : 6|2@0+ (1,0) [0|3] "" XXX
 SG_ NEW_SIGNAL_1 : 27|1@0+ (1,0) [0|1] "" XXX

BO_ 1244 iEloop_STATUS: 8 XXX
 SG_ NEW_SIGNAL_1 : 17|10@0+ (1,0) [0|1023] "" XXX
 SG_ NEW_SIGNAL_2 : 56|8@1+ (1,0) [0|255] "" XXX

BO_ 1266 MSG_09: 8 XXX
 SG_ NEW_SIGNAL_2 : 19|4@0+ (1,0) [0|1] "" XXX
 SG_ NEW_SIGNAL_1 : 20|1@0+ (1,0) [0|255] "" XXX
 SG_ NEW_SIGNAL_3 : 31|1@0+ (1,0) [0|255] "" XXX

BO_ 1267 MSG_10: 8 XXX
 SG_ NEW_SIGNAL_1 : 40|1@0+ (1,0) [0|16777215] "" XXX
 SG_ NEW_SIGNAL_2 : 42|1@0+ (1,0) [0|1] "" XXX

BO_ 1272 MSG_17: 8 XXX

BO_ 1274 EATC_INFO: 8 XXX
 SG_ SdsActvStat_D_Rq_2 : 2|3@1+ (1,0) [0|7] "" XXX
 SG_ SdsSmothStat_D_Rq_2 : 5|3@1+ (1,0) [0|7] "" XXX
 SG_ Sds_TotSD_Point_D_Actl_2 : 8|8@1+ (1,0) [0|255] "" XXX
 SG_ Engine_Load : 20|7@0+ (1,0) [0|127] "" XXX
 SG_ Sds_TotNG_Par_D_Rq_2 : 21|3@1+ (1,0) [0|7] "" XXX
 SG_ DR_Slope : 24|6@1+ (1,0) [0|63] "" XXX
 SG_ DR_IntakeAirTemp : 32|8@1+ (1,0) [0|255] "" XXX
 SG_ Unknown_40 : 40|1@1+ (1,0) [0|1] "" XXX
 SG_ OIL_DETERIORATE_LEVEL : 41|4@1+ (1,0) [0|15] "" XXX
 SG_ Clutch_SW : 45|1@1+ (1,0) [0|1] "" XXX
 SG_ Neutral_SW : 46|1@1+ (1,0) [0|1] "" XXX
 SG_ Fault_Status : 47|1@1+ (1,0) [0|1] "" XXX
 SG_ IDM_SD_CalcInfo_Value : 52|7@0+ (1,0) [0|127] "" XXX
 SG_ IDM_SD_CalcInfo_Category : 53|3@1+ (1,0) [0|7] "" XXX
 SG_ OilLevelSensWarn_B_Rq : 57|1@1+ (1,0) [0|1] "" XXX
 SG_ OilLevelStatusMonitor : 58|4@1+ (1,0) [0|15] "" XXX

BO_ 1275 2017_5: 8 XXX
 SG_ counter : 4|5@0+ (1,0) [0|255] "" XXX

BO_ 1277 NEW_MSG_10: 8 XXX
 SG_ counter : 7|8@0+ (1,0) [0|255] "" XXX
 SG_ NEW_SIGNAL_2 : 15|8@0+ (1,0) [0|255] "" XXX
 SG_ NEW_SIGNAL_3 : 31|8@0+ (1,0) [0|255] "" XXX

BO_ 1416 MSG_18: 8 XXX

BO_ 1425 MSG_19: 8 XXX

BO_ 1479 NEW_MSG_470: 8 XXX

CM_ SG_ 120 VEHICLE_ACC_X "Vehicle acceleration of X-axis wrt. NED frame.";
CM_ SG_ 120 VEHICLE_ACC_Y "Vehicle acceleration of Y-axis wrt. NED frame.";
CM_ SG_ 157 CAN_OFF "Disengage Cruise if enabled, if already disabled  TURN it OFF";
CM_ SG_ 357 GEAR "13P, 26R, 13N, 24D";
CM_ SG_ 540 LANE_LINE_VISIBLE "Inverse value of CAM_LKAS signal Line Not Visible.";
CM_ SG_ 540 LANE_LINE_TYPE "Matches CRZ_CTRL signal Lane Lines";
CM_ SG_ 540 WARN_POPUP_DISPLAY_REQUEST "This signal seems to be triggered before non-critical alerts are displayed, but not for all alerts. For example, brake warning does not seem to need this.";
CM_ SG_ 552 GEAR "0 Shifting, 1 P, 2 R, 3 N, 4 D";
CM_ SG_ 552 GEAR_BOX "0 P, 14 R, 1 though 6 D for speeds, 15 Shift";
CM_ SG_ 579 STEERING_ANGLE "steering angle aligns with 0.022 factor and -45.06 offset";
CM_ SG_ 605 BRAKE_WARNING "Flashing brake warning and audible alert for potential forward collision";
CM_ SG_ 1045 ABS_MALFUNCTION "off: 0, solid: 1, slow blink: 2, fast blink: 3";
CM_ SG_ 1088 LANE_LINES "0 LKAS disabled, 1 no lines, 2 two lines, 3 left line, 4 right line";
CM_ SG_ 1143 REAR_CT_ALERT "Rear Cross Traffic Alert";
CM_ SG_ 1157 LKAS_SENSETIVITY "0 low, 1 high";
CM_ SG_ 1157 WARNING "1 Rare, 0 often";
CM_ SG_ 1157 LKAS_ASSIT_TIMING "1 at, 0 before";
CM_ SG_ 1157 LANEE_DEPARTURE_ALERT "1 off, 2 on";
CM_ SG_ 1157 SBS_WARNING_DISTANCE "1 far, 2 mid, 3 near";
CM_ SG_ 1157 SBS_SCBC "1 off, 2 on";
VAL_ 540 LANE_LINE_VISIBLE 1 "Line Visible" 0 "Line Not Visible";
VAL_ 540 LANE_LINE_TYPE 0 "Main Cruise Disabled" 2 "Left/Right Lines Detected" 1 "Line Not Visible";
VAL_ 540 WARN_POPUP_DISPLAY_REQUEST 1 "Warn PopUp Request";
VAL_ 540 DRSS_DISTANCE 0 "No lead" 1 "Very far" 2 "Far" 3 "Mid" 4 "Close";
VAL_ 552 GEAR 1 "P" 2 "R" 3 "N" 4 "D";
